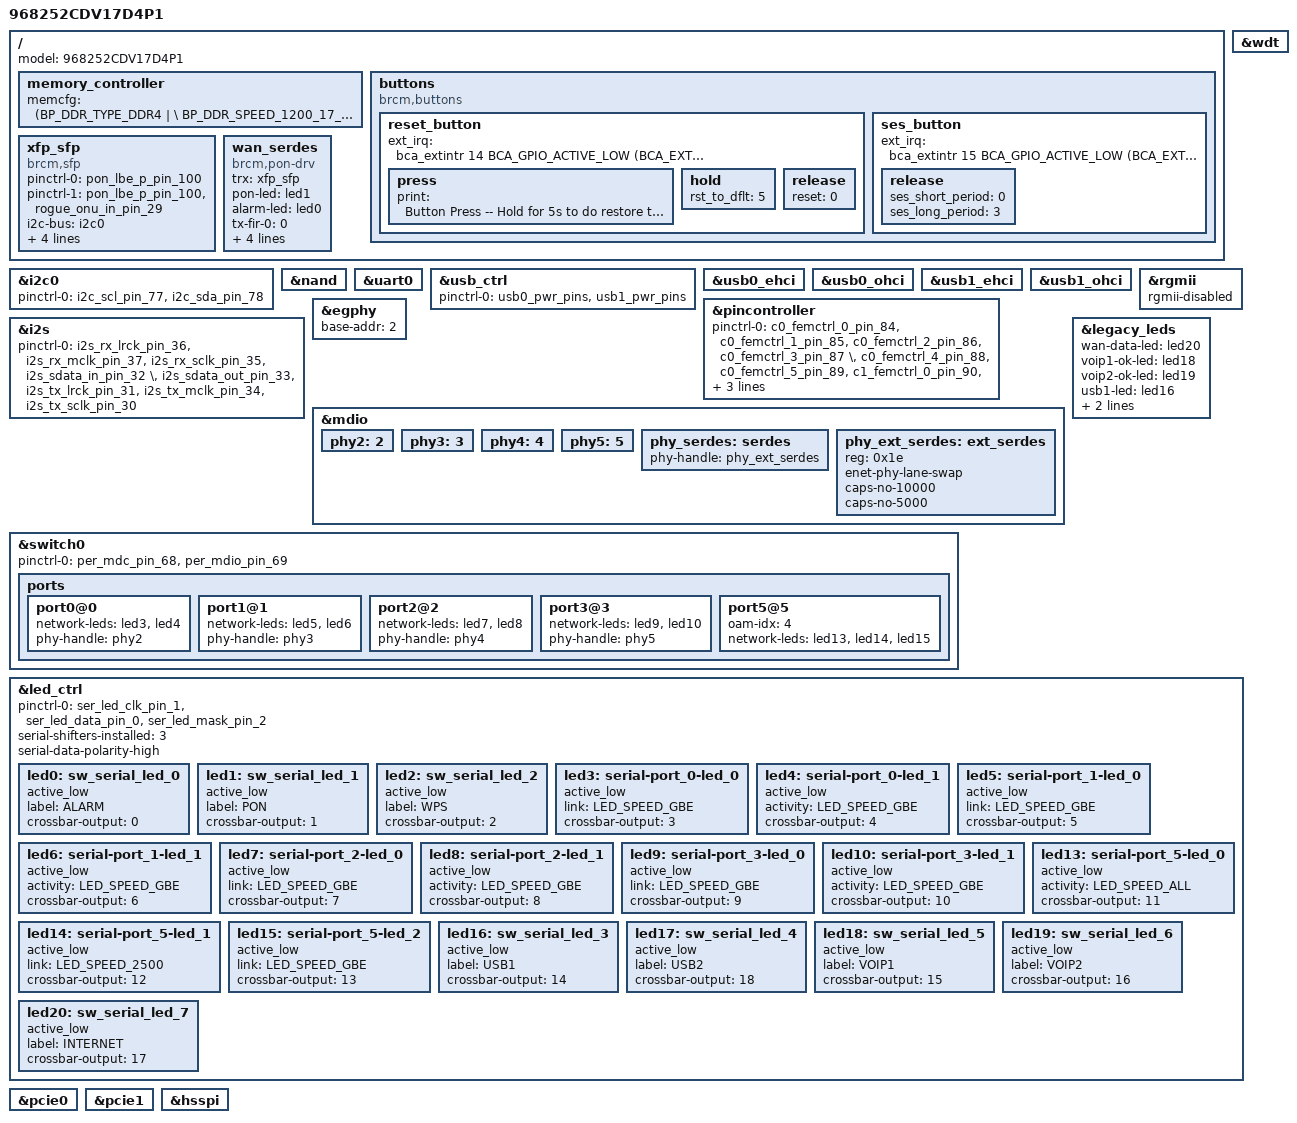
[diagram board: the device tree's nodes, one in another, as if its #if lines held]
#include "inc/6753.dtsi"

/ {
	memory_controller {
		memcfg = <(BP_DDR_TYPE_DDR4            | \
                    BP_DDR_SPEED_1200_17_17_17 | \
					BP_DDR_TOTAL_SIZE_1024MB   | \
					BP_DDR_DEVICE_WIDTH_16     | \
					BP_DDR_TOTAL_WIDTH_16BIT   | \
					BP_DDR_SSC_CONFIG_1)>;
	};
};

/ {
    model = "968252CDV17D4P1"; // "968252CDV17_DDR4_PCIX1"

    buttons {
        compatible = "brcm,buttons";
        reset_button {
            ext_irq = <&bca_extintr 14 BCA_GPIO_ACTIVE_LOW (BCA_EXTINTR_TYPE_LOW_LEVEL | BCA_EXTINTR_TYPE_SENSE_EDGE)>;
            press {
                print = "Button Press -- Hold for 5s to do restore to default";
            };
            hold {
                rst_to_dflt = <5>;
            };
            release {
                reset = <0>;
            };
        };
        ses_button {
            ext_irq = <&bca_extintr 15 BCA_GPIO_ACTIVE_LOW (BCA_EXTINTR_TYPE_LOW_LEVEL | BCA_EXTINTR_TYPE_SENSE_EDGE)>;
            release {
                ses_short_period = <0>;
                ses_long_period = <3>;
            };
        };
    };

    xfp_sfp: xfp_sfp {
        compatible = "brcm,sfp";
        pinctrl-names = "default", "tx-sd";
        pinctrl-0 = <&pon_lbe_p_pin_100>;
        pinctrl-1 = <&pon_lbe_p_pin_100 &rogue_onu_in_pin_29>;
        i2c-bus = <&i2c0>;
        los-gpio = <&gpioc 12 GPIO_ACTIVE_HIGH>;
        mod-def0 = <&bca_extintr 9 GPIO_ACTIVE_LOW (BCA_EXTINTR_TYPE_BOTH_EDGE | BCA_EXTINTR_TYPE_SENSE_EDGE)>;
        tx-power-gpio = <&gpioc 13 GPIO_ACTIVE_HIGH>;
    };

    wan_serdes {
            compatible = "brcm,pon-drv";
            trx = <&xfp_sfp>;
            pon-led = <&led1>;
            alarm-led = <&led0>;
            tx-fir-0 = "0";
            tx-fir-1 = "70";
            tx-fir-2 = "35";
            tx-fir-3 = "0";
            tx-fir-4 = "7";
    };

};

&i2c0 {
    pinctrl-0 = <&i2c_scl_pin_77 &i2c_sda_pin_78>;
    pinctrl-names = "default";
    status = "okay";
};
&nand {
	status = "okay";
};
&wdt {
	status = "okay";
};
&uart0 {
	status = "okay";
};

&usb_ctrl {
    pinctrl-names = "default";
    pinctrl-0 = <&usb0_pwr_pins &usb1_pwr_pins>;
    status = "okay";
};
&usb0_ehci {
    status = "okay";
};
&usb0_ohci {
    status = "okay";
};
&usb1_ehci {
    status = "okay";
};
&usb1_ohci {
    status = "okay";
};

&pincontroller {
    pinctrl-names = "default";
    pinctrl-0 = <&c0_femctrl_0_pin_84 &c0_femctrl_1_pin_85 &c0_femctrl_2_pin_86 &c0_femctrl_3_pin_87 \
                 &c0_femctrl_4_pin_88 &c0_femctrl_5_pin_89 &c1_femctrl_0_pin_90 &c1_femctrl_1_pin_91 \
                 &c1_femctrl_2_pin_92 &c1_femctrl_3_pin_93 &c1_femctrl_4_pin_94 &c1_femctrl_5_pin_95 >;
};

&i2s {
        pinctrl-0 = <&i2s_rx_lrck_pin_36 &i2s_rx_mclk_pin_37 &i2s_rx_sclk_pin_35 &i2s_sdata_in_pin_32 \
                     &i2s_sdata_out_pin_33 &i2s_tx_lrck_pin_31 &i2s_tx_mclk_pin_34 &i2s_tx_sclk_pin_30 >;
        pinctrl-names = "default";
        status = "okay";
};

&rgmii {
        rgmii-disabled;
        status = "okay";
};

&egphy {
        base-addr = <2>;
};

&mdio {
        phy2:2 {
                status = "okay";
        };

        phy3:3 {
                status = "okay";
        };

        phy4:4 {
                status = "okay";
        };

        phy5:5 {
                status = "okay";
        };

        phy_serdes: serdes {
                phy-handle = <&phy_ext_serdes>;
                status = "okay";
        };

        phy_ext_serdes: ext_serdes {
                reg = <0x1e>;
                enet-phy-lane-swap;
                caps-no-10000;
                caps-no-5000;
                status = "okay";
        };
};

&switch0 {
        pinctrl-names = "default";
        pinctrl-0 = <&per_mdc_pin_68 &per_mdio_pin_69>;

        ports {
                port0@0 {
                        network-leds = <&led3 &led4>;
                        phy-handle = <&phy2>;
                        status = "okay";
                };

                port1@1 {
                        network-leds = <&led5 &led6>;
                        phy-handle = <&phy3>;
                        status = "okay";
                };

                port2@2 {
                        network-leds = <&led7 &led8>;
                        phy-handle = <&phy4>;
                        status = "okay";
                };

                port3@3 {
                        network-leds = <&led9 &led10>;
                        phy-handle = <&phy5>;
                        status = "okay";
                };

                port5@5 {
                        oam-idx = <4>;
                        network-leds = <&led13 &led14 &led15>;
                        status = "okay";
                };
        };
};

&legacy_leds {
    wan-data-led = <&led20>;
    voip1-ok-led = <&led18>;
    voip2-ok-led = <&led19>;
    usb1-led = <&led16>;
    usb2-led = <&led17>;
    wl-sess-led = <&led2>;
};

&led_ctrl {
    pinctrl-names = "default";
    pinctrl-0 = <&ser_led_clk_pin_1 &ser_led_data_pin_0 &ser_led_mask_pin_2>;
    serial-shifters-installed = <3>;
    serial-data-polarity-high;

    led0: sw_serial_led_0 {
        active_low;
        label = "ALARM";
        crossbar-output = <0>;
        status = "okay";
    };

    led1: sw_serial_led_1 {
        active_low;
        label = "PON";
        crossbar-output = <1>;
        status = "okay";
    };

    led2: sw_serial_led_2 {
        active_low;
        label = "WPS";
        crossbar-output = <2>;
        status = "okay";
    };

    led3: serial-port_0-led_0 {
        active_low;
        link = <LED_SPEED_GBE>;
        crossbar-output = <3>;
        status = "okay";
    };

    led4: serial-port_0-led_1 {
        active_low;
        activity = <LED_SPEED_GBE>;
        crossbar-output = <4>;
        status = "okay";
    };

    led5: serial-port_1-led_0 {
        active_low;
        link = <LED_SPEED_GBE>;
        crossbar-output = <5>;
        status = "okay";
    };

    led6: serial-port_1-led_1 {
        active_low;
        activity = <LED_SPEED_GBE>;
        crossbar-output = <6>;
        status = "okay";
    };

    led7: serial-port_2-led_0 {
        active_low;
        link = <LED_SPEED_GBE>;
        crossbar-output = <7>;
        status = "okay";
    };

    led8: serial-port_2-led_1 {
        active_low;
        activity = <LED_SPEED_GBE>;
        crossbar-output = <8>;
        status = "okay";
    };

    led9: serial-port_3-led_0 {
        active_low;
        link = <LED_SPEED_GBE>;
        crossbar-output = <9>;
        status = "okay";
    };

    led10: serial-port_3-led_1 {
        active_low;
        activity = <LED_SPEED_GBE>;
        crossbar-output = <10>;
        status = "okay";
    };

    led13: serial-port_5-led_0 {
        active_low;
        activity = <LED_SPEED_ALL>;
        crossbar-output = <11>;
        status = "okay";
    };

    led14: serial-port_5-led_1 {
        active_low;
        link = <LED_SPEED_2500>;
        crossbar-output = <12>;
        status = "okay";
    };

    led15: serial-port_5-led_2 {
        active_low;
        link = <LED_SPEED_GBE>;
        crossbar-output = <13>;
        status = "okay";
    };

    led16: sw_serial_led_3 {
        active_low;
        label = "USB1";
        crossbar-output = <14>;
        status = "okay";
    };

    led17: sw_serial_led_4 {
        active_low;
        label = "USB2";
        crossbar-output = <18>;
        status = "okay";
    };

    led18: sw_serial_led_5 {
        active_low;
        label = "VOIP1";
        crossbar-output = <15>;
        status = "okay";
    };

    led19: sw_serial_led_6 {
        active_low;
        label = "VOIP2";
        crossbar-output = <16>;
        status = "okay";
    };

    led20: sw_serial_led_7 {
        active_low;
        label = "INTERNET";
        crossbar-output = <17>;
        status = "okay";
    };
};

#if defined(CONFIG_BCM_PCIE_HCD) || defined(CONFIG_BCM_PCIE_HCD_MODULE)
&pcie0 {
    status = "okay";
};
&pcie1 {
    status = "okay";
};
#endif

&hsspi {
	status = "okay";
};
